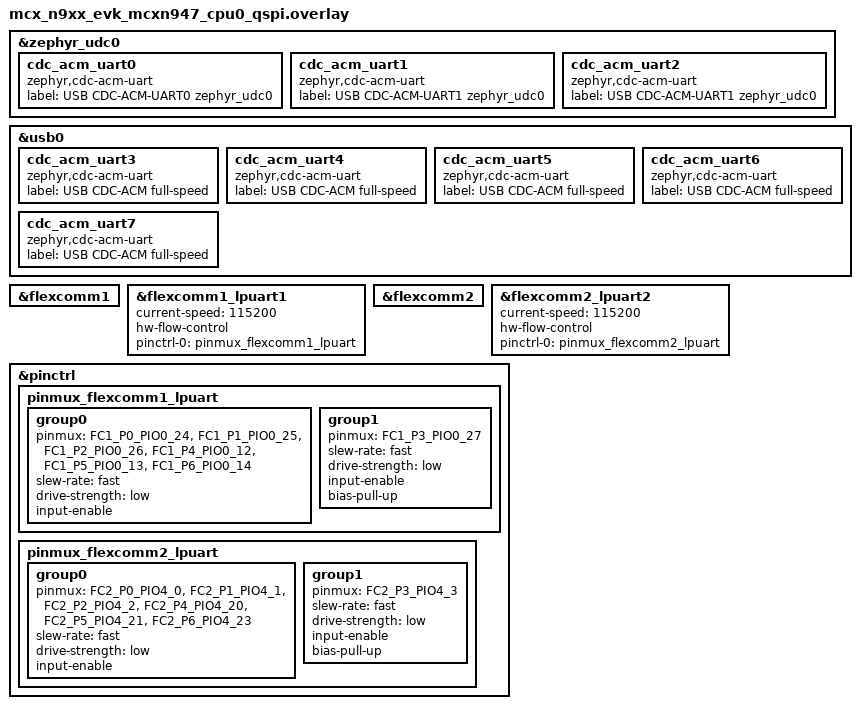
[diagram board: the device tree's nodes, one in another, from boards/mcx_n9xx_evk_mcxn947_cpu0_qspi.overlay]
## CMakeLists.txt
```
# SPDX-License-Identifier: Apache-2.0

cmake_minimum_required(VERSION 3.20.0)
find_package(Zephyr REQUIRED HINTS $ENV{ZEPHYR_BASE})
project(cdc_multi)

include(${ZEPHYR_BASE}/samples/subsys/usb/common/common.cmake)
target_include_directories(app PRIVATE src)
list(APPEND app_sources src/main.c)
list(APPEND app_sources src/dual_usbd_init.c)

if (DEFINED CONFIG_APP_UART_TEST)
	list(APPEND app_sources src/uart_test.c)
endif()

target_sources(app PRIVATE ${app_sources})
```

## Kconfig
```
# Copyright (c) 2023 Nordic Semiconductor ASA
# Copyright 2025 NXP
# SPDX-License-Identifier: Apache-2.0

config APP_UART_TEST
	bool
	prompt "Includes UART test in app"

module = UART_TEST
module-str = uart_test
source "subsys/logging/Kconfig.template.log_config"

# Source common USB sample options used to initialize new experimental USB
# device stack. The scope of these options is limited to USB samples in project
# tree, you cannot use them in your own application.
source "samples/subsys/usb/common/Kconfig.sample_usbd"

source "Kconfig.zephyr"
```

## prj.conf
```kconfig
CONFIG_USB_DEVICE_STACK_NEXT=y

CONFIG_STDOUT_CONSOLE=y
CONFIG_SERIAL=y
CONFIG_UART_LINE_CTRL=y
CONFIG_UART_INTERRUPT_DRIVEN=y

CONFIG_LOG=y
CONFIG_USBD_LOG_LEVEL_WRN=y
CONFIG_UDC_DRIVER_LOG_LEVEL_WRN=y
CONFIG_USBD_CDC_ACM_LOG_LEVEL_ERR=y

CONFIG_USB_DEVICE_INITIALIZE_AT_BOOT=n
CONFIG_CDC_ACM_SERIAL_INITIALIZE_AT_BOOT=n
CONFIG_USBD_CDC_ACM_CLASS=y


CONFIG_SAMPLE_USBD_PID=0x0001
CONFIG_SAMPLE_USBD_PRODUCT="USBD CDC Multi sample"

CONFIG_APP_UART_TEST=y
CONFIG_UART_TEST_LOG_LEVEL_DBG=y
```

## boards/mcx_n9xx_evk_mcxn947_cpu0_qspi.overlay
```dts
/*
 * Copyright 2025 NXP
 *
 * SPDX-License-Identifier: Apache-2.0
 */

/* For USBHS && USBFS */
&zephyr_udc0 {
	cdc_acm_uart0 {
		compatible = "zephyr,cdc-acm-uart";
		label = "USB CDC-ACM-UART0 zephyr_udc0";
	};

	cdc_acm_uart1 {
		compatible = "zephyr,cdc-acm-uart";
		label = "USB CDC-ACM-UART1 zephyr_udc0";
	};

	cdc_acm_uart2 {
		compatible = "zephyr,cdc-acm-uart";
		label = "USB CDC-ACM-UART1 zephyr_udc0";
	};
};

zephyr_udc1: &usb0 {
	status = "okay";
	cdc_acm_uart3 {
		compatible = "zephyr,cdc-acm-uart";
		label = "USB CDC-ACM full-speed";
	};

	cdc_acm_uart4 {
		compatible = "zephyr,cdc-acm-uart";
		label = "USB CDC-ACM full-speed";
	};

	cdc_acm_uart5 {
		compatible = "zephyr,cdc-acm-uart";
		label = "USB CDC-ACM full-speed";
	};

	cdc_acm_uart6 {
		compatible = "zephyr,cdc-acm-uart";
		label = "USB CDC-ACM full-speed";
	};

	cdc_acm_uart7 {
		compatible = "zephyr,cdc-acm-uart";
		label = "USB CDC-ACM full-speed";
	};
};

/* For UARTs test with hardware flow control */
&flexcomm1 {
	status = "okay";
};

test_uart1: &flexcomm1_lpuart1 {
	status = "okay";
	current-speed = <115200>;
	hw-flow-control;
	pinctrl-0 = < &pinmux_flexcomm1_lpuart >;
	pinctrl-names = "default";
};

&flexcomm2 {
	status = "okay";
};

test_uart2: &flexcomm2_lpuart2 {
		status = "okay";
		current-speed = <115200>;
		hw-flow-control;
		pinctrl-0 = < &pinmux_flexcomm2_lpuart >;
		pinctrl-names = "default";
};

&pinctrl {
	pinmux_flexcomm1_lpuart: pinmux_flexcomm1_lpuart {
		group0 {
			pinmux = <FC1_P0_PIO0_24>,
				<FC1_P1_PIO0_25>,
				<FC1_P2_PIO0_26>,
				<FC1_P4_PIO0_12>,
				<FC1_P5_PIO0_13>,
				<FC1_P6_PIO0_14>;
			slew-rate = "fast";
			drive-strength = "low";
			input-enable;
		};
		group1 {
			/* Pull-up CTS_b signals */
			pinmux = <FC1_P3_PIO0_27>;
			slew-rate = "fast";
			drive-strength = "low";
			input-enable;
			bias-pull-up;
		};
	};

	pinmux_flexcomm2_lpuart: pinmux_flexcomm2_lpuart {
		group0 {
			pinmux = <FC2_P0_PIO4_0>,
				<FC2_P1_PIO4_1>,
				<FC2_P2_PIO4_2>,
				<FC2_P4_PIO4_20>,
				<FC2_P5_PIO4_21>,
				<FC2_P6_PIO4_23>;
			slew-rate = "fast";
			drive-strength = "low";
			input-enable;
		};
		group1 {
			/* Pull-up CTS_b signals */
			pinmux = <FC2_P3_PIO4_3>;
			slew-rate = "fast";
			drive-strength = "low";
			input-enable;
			bias-pull-up;
		};
	};
};
```

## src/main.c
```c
/*
 * Copyright (c) 2019 Intel Corporation
 *
 * SPDX-License-Identifier: Apache-2.0
 */

/**
 * @file
 * @brief Sample echo app for CDC ACM class
 *
 * Sample app for USB CDC ACM class driver. The received data is echoed back
 * to the serial port.
 */

#include <dual_usbd.h>

#include <stdio.h>
#include <string.h>
#include <zephyr/device.h>
#include <zephyr/drivers/uart.h>
#include <zephyr/kernel.h>
#include <zephyr/sys/ring_buffer.h>

#include <zephyr/usb/usb_device.h>
#include <zephyr/usb/usbd.h>
#include <zephyr/logging/log.h>
LOG_MODULE_REGISTER(cdc_acm_echo, LOG_LEVEL_INF);

const struct device *const uart0_dev = DEVICE_DT_GET_ONE(zephyr_cdc_acm_uart);

#define RING_BUF_SIZE 1024
uint8_t ring_buffer[RING_BUF_SIZE];

struct ring_buf ringbuf;

static bool rx_throttled;

static struct usbd_context *usb0_ctx;
static struct usbd_context *usb1_ctx;

K_SEM_DEFINE(usb0_dtr_sem, 0, 1);
K_SEM_DEFINE(usb1_dtr_sem, 0, 1);

static inline void print_baudrate(const struct device *dev)
{
	uint32_t baudrate;
	int ret;

	ret = uart_line_ctrl_get(dev, UART_LINE_CTRL_BAUD_RATE, &baudrate);
	if (ret) {
		LOG_WRN("Failed to get baudrate, ret code %d", ret);
	} else {
		LOG_INF("Baudrate %u", baudrate);
	}
}


static void usb0_msg_cb(struct usbd_context *const ctx, const struct usbd_msg *msg)
{
	LOG_INF("USBD message: %s", usbd_msg_type_string(msg->type));

	if (usbd_can_detect_vbus(ctx)) {
		if (msg->type == USBD_MSG_VBUS_READY) {
			if (usbd_enable(ctx)) {
				LOG_ERR("Failed to enable device support");
			}
		}

		if (msg->type == USBD_MSG_VBUS_REMOVED) {
			if (usbd_disable(ctx)) {
				LOG_ERR("Failed to disable device support");
			}
		}
	}

	if (msg->type == USBD_MSG_CDC_ACM_CONTROL_LINE_STATE) {
		uint32_t usb0_dtr = 0U;

		uart_line_ctrl_get(msg->dev, UART_LINE_CTRL_DTR, &usb0_dtr);
		if (usb0_dtr) {
			k_sem_give(&usb0_dtr_sem);
		}
	}

	if (msg->type == USBD_MSG_CDC_ACM_LINE_CODING) {
		print_baudrate(msg->dev);
	}
}

static void usb1_msg_cb(struct usbd_context *const ctx, const struct usbd_msg *msg)
{
	LOG_INF("USBD message: %s", usbd_msg_type_string(msg->type));

	if (usbd_can_detect_vbus(ctx)) {
		if (msg->type == USBD_MSG_VBUS_READY) {
			if (usbd_enable(ctx)) {
				LOG_ERR("Failed to enable device support");
			}
		}

		if (msg->type == USBD_MSG_VBUS_REMOVED) {
			if (usbd_disable(ctx)) {
				LOG_ERR("Failed to disable device support");
			}
		}
	}

	if (msg->type == USBD_MSG_CDC_ACM_CONTROL_LINE_STATE) {
		uint32_t usb1_dtr = 0U;

		uart_line_ctrl_get(msg->dev, UART_LINE_CTRL_DTR, &usb1_dtr);
		if (usb1_dtr) {
			k_sem_give(&usb1_dtr_sem);
		}
	}

	if (msg->type == USBD_MSG_CDC_ACM_LINE_CODING) {
		print_baudrate(msg->dev);
	}
}

static int enable_usb_device_next(void)
{
	int err;

	usb0_ctx = usb0_init_device(usb0_msg_cb);
	if (usb0_ctx == NULL) {
		LOG_ERR("Failed to initialize usb0 device");
		return -ENODEV;
	}

	if (!usbd_can_detect_vbus(usb0_ctx)) {
		err = usbd_enable(usb0_ctx);
		if (err) {
			LOG_ERR("Failed to enable device support");
		} else {
			LOG_INF("usb0 enabled");
		}
	}

	usb1_ctx = usb1_init_device(usb1_msg_cb);
	if (usb1_ctx == NULL) {
		LOG_ERR("Failed to initialize usb0 device");
		return -ENODEV;
	}

	if (!usbd_can_detect_vbus(usb1_ctx)) {
		err = usbd_enable(usb1_ctx);
		if (err) {
			LOG_ERR("Failed to enable usb1 device support");
		} else {
			LOG_INF("usb1 enabled");
		}
	}

	return 0;
}

static void interrupt_handler(const struct device *dev, void *user_data)
{
	ARG_UNUSED(user_data);

	while (uart_irq_update(dev) && uart_irq_is_pending(dev)) {
		if (!rx_throttled && uart_irq_rx_ready(dev)) {
			int recv_len, rb_len;
			uint8_t buffer[64];
			size_t len = MIN(ring_buf_space_get(&ringbuf),
					 sizeof(buffer));

			if (len == 0) {
				/* Throttle because ring buffer is full */
				uart_irq_rx_disable(dev);
				rx_throttled = true;
				continue;
			}

			recv_len = uart_fifo_read(dev, buffer, len);
			if (recv_len < 0) {
				LOG_ERR("Failed to read UART FIFO");
				recv_len = 0;
			};

			rb_len = ring_buf_put(&ringbuf, buffer, recv_len);
			if (rb_len < recv_len) {
				LOG_ERR("Drop %u bytes", recv_len - rb_len);
			}

			LOG_DBG("tty fifo -> ringbuf %d bytes", rb_len);
			if (rb_len) {
				uart_irq_tx_enable(dev);
			}
		}

		if (uart_irq_tx_ready(dev)) {
			uint8_t buffer[64];
			int rb_len, send_len;

			rb_len = ring_buf_get(&ringbuf, buffer, sizeof(buffer));
			if (!rb_len) {
				LOG_DBG("Ring buffer empty, disable TX IRQ");
				uart_irq_tx_disable(dev);
				continue;
			}

			if (rx_throttled) {
				uart_irq_rx_enable(dev);
				rx_throttled = false;
			}

			send_len = uart_fifo_fill(dev, buffer, rb_len);
			if (send_len < rb_len) {
				LOG_ERR("Drop %d bytes", rb_len - send_len);
			}

			LOG_DBG("ringbuf -> tty fifo %d bytes", send_len);
		}
	}
}

int main(void)
{
	int ret;

	if (!device_is_ready(uart0_dev)) {
		LOG_ERR("CDC ACM device not ready");
		return 0;
	}

	ret = enable_usb_device_next();
	if (ret != 0) {
		LOG_ERR("Failed to enable USB");
		return 0;
	}

	ring_buf_init(&ringbuf, sizeof(ring_buffer), ring_buffer);
	LOG_INF("Wait for DTR");

#if defined(CONFIG_USB_DEVICE_STACK_NEXT)
	k_sem_take(&usb0_dtr_sem, K_FOREVER);
#else
	while (true) {
		uint32_t dtr = 0U;

		uart_line_ctrl_get(uart_dev, UART_LINE_CTRL_DTR, &dtr);
		if (dtr) {
			break;
		} else {
			/* Give CPU resources to low priority threads. */
			k_sleep(K_MSEC(100));
		}
	}
#endif

	LOG_INF("DTR set");

	/* They are optional, we use them to test the interrupt endpoint */
	ret = uart_line_ctrl_set(uart0_dev, UART_LINE_CTRL_DCD, 1);
	if (ret) {
		LOG_WRN("Failed to set DCD, ret code %d", ret);
	}

	ret = uart_line_ctrl_set(uart0_dev, UART_LINE_CTRL_DSR, 1);
	if (ret) {
		LOG_WRN("Failed to set DSR, ret code %d", ret);
	}

	/* Wait 100ms for the host to do all settings */
	k_msleep(100);

#ifndef CONFIG_USB_DEVICE_STACK_NEXT
	print_baudrate(uart0_dev);
#endif
	uart_irq_callback_set(uart0_dev, interrupt_handler);

	/* Enable rx interrupts */
	uart_irq_rx_enable(uart0_dev);

	return 0;
}
```

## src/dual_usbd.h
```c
/*
 * Copyright (c) 2023 Nordic Semiconductor ASA.
 *
 * SPDX-License-Identifier: Apache-2.0
 */

#ifndef ZEPHYR_SAMPLES_SUBSYS_USB_COMMON_SAMPLE_USBD_H
#define ZEPHYR_SAMPLES_SUBSYS_USB_COMMON_SAMPLE_USBD_H

#include <stdint.h>
#include <zephyr/usb/usbd.h>

/*
 * The scope of this header is limited to use in USB samples together with the
 * new experimental USB device stack, you should not use it in your own
 * application. However, you can use the code as a template.
 */

/*
 * This function uses Kconfig.sample_usbd options to configure and initialize a
 * USB device. It configures sample's device context, default string descriptors,
 * USB device configuration, registers any available class instances, and
 * finally initializes USB device. It is limited to a single device with a
 * single configuration instantiated in sample_usbd_init.c, which should be
 * enough for a simple USB device sample.
 *
 * It returns the configured and initialized USB device context on success,
 * otherwise it returns NULL.
 */
/* struct usbd_context *sample_usbd_init_device(usbd_msg_cb_t msg_cb, enum usbd_speed speed); */

/*
 * This function is similar to sample_usbd_init_device(), but does not
 * initialize the device. It allows the application to set additional features,
 * such as additional descriptors.
 */
/* struct usbd_context *sample_usbd_setup_device(usbd_msg_cb_t msg_cb); */

struct usbd_context *usb0_init_device(usbd_msg_cb_t msg_cb);
struct usbd_context *usb1_init_device(usbd_msg_cb_t msg_cb);

#endif /* ZEPHYR_SAMPLES_SUBSYS_USB_COMMON_SAMPLE_USBD_H */
```

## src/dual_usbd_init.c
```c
/*
 * Copyright (c) 2023 Nordic Semiconductor ASA
 *
 * SPDX-License-Identifier: Apache-2.0
 */

#include <stdint.h>

#include <zephyr/init.h>
#include <zephyr/kernel.h>
#include <zephyr/device.h>
#include <zephyr/usb/usbd.h>

#include <zephyr/logging/log.h>
LOG_MODULE_REGISTER(dual_usbd, LOG_LEVEL_DBG);

#define ZEPHYR_PROJECT_USB_VID 0x2fe3

USBD_DEVICE_DEFINE(usb0_usbd, DEVICE_DT_GET(DT_NODELABEL(zephyr_udc0)),
	ZEPHYR_PROJECT_USB_VID, CONFIG_SAMPLE_USBD_PID);

USBD_DEVICE_DEFINE(usb1_usbd, DEVICE_DT_GET(DT_NODELABEL(zephyr_udc1)),
	ZEPHYR_PROJECT_USB_VID, CONFIG_SAMPLE_USBD_PID);

USBD_DESC_LANG_DEFINE(usb0_lang);
USBD_DESC_MANUFACTURER_DEFINE(usb0_mfr, CONFIG_SAMPLE_USBD_MANUFACTURER);
USBD_DESC_PRODUCT_DEFINE(usb0_product, CONFIG_SAMPLE_USBD_PRODUCT);
USBD_DESC_SERIAL_NUMBER_DEFINE(usb0_sn);

USBD_DESC_LANG_DEFINE(usb1_lang);
USBD_DESC_MANUFACTURER_DEFINE(usb1_mfr, CONFIG_SAMPLE_USBD_MANUFACTURER);
USBD_DESC_PRODUCT_DEFINE(usb1_product, CONFIG_SAMPLE_USBD_PRODUCT);
USBD_DESC_SERIAL_NUMBER_DEFINE(usb1_sn);


USBD_DESC_CONFIG_DEFINE(usb_fs_cfg_desc, "FS Configuration");
USBD_DESC_CONFIG_DEFINE(usb_hs_cfg_desc, "HS Configuration");

/* doc configuration instantiation start */
static const uint8_t attributes =
	(IS_ENABLED(CONFIG_SAMPLE_USBD_SELF_POWERED) ? USB_SCD_SELF_POWERED : 0) |
	(IS_ENABLED(CONFIG_SAMPLE_USBD_REMOTE_WAKEUP) ? USB_SCD_REMOTE_WAKEUP : 0);

/* Speed configuration */
USBD_CONFIGURATION_DEFINE(usb_fs_config, attributes,
			CONFIG_SAMPLE_USBD_MAX_POWER, &usb_fs_cfg_desc);
USBD_CONFIGURATION_DEFINE(usb_hs_config, attributes,
			CONFIG_SAMPLE_USBD_MAX_POWER, &usb_hs_cfg_desc);
/* doc configuration instantiation end */

static int usb0_register_cdc_acm_n(struct usbd_context *const uds_ctx,
			const enum usbd_speed speed)
{
	struct usbd_config_node *cfg_nd;
	int err;

	if (speed == USBD_SPEED_HS) {
		cfg_nd = &usb_hs_config;
	} else {
		cfg_nd = &usb_fs_config;
	}

	err = usbd_add_configuration(uds_ctx, speed, cfg_nd);
	if (err) {
		LOG_ERR("Failed to add configuration");
		return err;
	}

	err = usbd_register_class(uds_ctx, "cdc_acm_0", speed, 1);
	if (err) {
		LOG_ERR("Failed to register cdc_acm0");
		return err;
	}

	err = usbd_register_class(uds_ctx, "cdc_acm_1", speed, 1);
	if (err) {
		LOG_ERR("Failed to register cdc_acm1");
		return err;
	}

	err = usbd_register_class(uds_ctx, "cdc_acm_2", speed, 1);
	if (err) {
		LOG_ERR("Failed to register cdc_acm2");
		return err;
	}

	return usbd_device_set_code_triple(uds_ctx, speed, USB_BCC_MISCELLANEOUS, 0x02, 0x01);
}

static int usb1_register_cdc_acm_n(struct usbd_context *const uds_ctx,
	const enum usbd_speed speed)
{
	struct usbd_config_node *cfg_nd;
	int err;

	if (speed == USBD_SPEED_HS) {
		cfg_nd = &usb_hs_config;
	} else {
		cfg_nd = &usb_fs_config;
	}

	err = usbd_add_configuration(uds_ctx, speed, cfg_nd);
	if (err) {
		LOG_ERR("Failed to add configuration");
		return err;
	}

	err = usbd_register_class(uds_ctx, "cdc_acm_3", speed, 1);
	if (err) {
		LOG_ERR("Failed to register cdc_acm3");
		return err;
	}

	err = usbd_register_class(uds_ctx, "cdc_acm_4", speed, 1);
	if (err) {
		LOG_ERR("Failed to register cdc_acm4");
		return err;
	}

	err = usbd_register_class(uds_ctx, "cdc_acm_5", speed, 1);
	if (err) {
		LOG_ERR("Failed to register cdc_acm5");
		return err;
	}

	err = usbd_register_class(uds_ctx, "cdc_acm_6", speed, 1);
	if (err) {
		LOG_ERR("Failed to register cdc_acm6");
		return err;
	}

	err = usbd_register_class(uds_ctx, "cdc_acm_7", speed, 1);
	if (err) {
		LOG_ERR("Failed to register cdc_acm7");
		return err;
	}

	return usbd_device_set_code_triple(uds_ctx, speed, USB_BCC_MISCELLANEOUS, 0x02, 0x01);
}

struct usbd_context *usb0_init_device(usbd_msg_cb_t msg_cb)
{
	int err = 0;
	enum usbd_speed speed;

	err = usbd_add_descriptor(&usb0_usbd, &usb0_lang);
	if (err) {
		LOG_ERR("Failed to initialize language descriptor (%d)", err);
		return NULL;
	}

	err = usbd_add_descriptor(&usb0_usbd, &usb0_mfr);
	if (err) {
		LOG_ERR("Failed to initialize manufacturer descriptor (%d)", err);
		return NULL;
	}

	err = usbd_add_descriptor(&usb0_usbd, &usb0_product);
	if (err) {
		LOG_ERR("Failed to initialize product descriptor (%d)", err);
		return NULL;
	}

	err = usbd_add_descriptor(&usb0_usbd, &usb0_sn);
	if (err) {
		LOG_ERR("Failed to initialize SN descriptor (%d)", err);
		return NULL;
	}


	speed = usbd_caps_speed(&usb0_usbd);
	err = usb0_register_cdc_acm_n(&usb0_usbd, speed);
	if (err) {
		return NULL;
	}

	err = usbd_msg_register_cb(&usb0_usbd, msg_cb);
	if (err) {
		LOG_ERR("Failed to register message callback");
		return NULL;
	}

	err = usbd_init(&usb0_usbd);
	if (err) {
		LOG_ERR("Failed to initialize device support");
		return NULL;
	}

	return &usb0_usbd;
}

struct usbd_context *usb1_init_device(usbd_msg_cb_t msg_cb)
{
	int err = 0;
	enum usbd_speed speed;

	err = usbd_add_descriptor(&usb1_usbd, &usb1_lang);
	if (err) {
		LOG_ERR("Failed to initialize language descriptor (%d)", err);
		return NULL;
	}

	err = usbd_add_descriptor(&usb1_usbd, &usb1_mfr);
	if (err) {
		LOG_ERR("Failed to initialize manufacturer descriptor (%d)", err);
		return NULL;
	}

	err = usbd_add_descriptor(&usb1_usbd, &usb1_product);
	if (err) {
		LOG_ERR("Failed to initialize product descriptor (%d)", err);
		return NULL;
	}

	err = usbd_add_descriptor(&usb1_usbd, &usb1_sn);
	if (err) {
		LOG_ERR("Failed to initialize SN descriptor (%d)", err);
		return NULL;
	}


	speed = usbd_caps_speed(&usb1_usbd);
	err = usb1_register_cdc_acm_n(&usb1_usbd, speed);
	if (err) {
		return NULL;
	}

	err = usbd_msg_register_cb(&usb1_usbd, msg_cb);
	if (err) {
		LOG_ERR("Failed to register usb1 message callback");
		return NULL;
	}

	err = usbd_init(&usb1_usbd);
	if (err) {
		LOG_ERR("Failed to initialize device support");
		return NULL;
	}

	return &usb1_usbd;
}

/*
 * SYS_INIT(usb0_init_device, APPLICATION, CONFIG_APPLICATION_INIT_PRIORITY);
 * SYS_INIT(usb1_init_device, APPLICATION, CONFIG_APPLICATION_INIT_PRIORITY);
 */
```

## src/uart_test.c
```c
/*
 * Copyright 2025 NXP
 * Copyright (c) 2024 Nordic Semiconductor ASA
 *
 * SPDX-License-Identifier: Apache-2.0
 */

#include <zephyr/kernel.h>
#include <zephyr/device.h>
#include <zephyr/drivers/uart.h>

#ifdef CONFIG_LOG
	#include <zephyr/logging/log.h>
	LOG_MODULE_REGISTER(uart_test, CONFIG_UART_TEST_LOG_LEVEL);
#endif

#define UART1_NODE DT_NODELABEL(test_uart1)
#define UART2_NODE DT_NODELABEL(test_uart2)
static const struct device *const uart1_dev = DEVICE_DT_GET(UART1_NODE);
static const struct device *const uart2_dev = DEVICE_DT_GET(UART2_NODE);

#define SLEEP_TIME_MS 1000
#define TEST_BUFFER_LEN 20
const uint8_t test_pattern[TEST_BUFFER_LEN] = "UART Hello";
static uint8_t test1_buffer[TEST_BUFFER_LEN];
static uint8_t test2_buffer[TEST_BUFFER_LEN];
static volatile uint8_t uart1_error_counter;
static volatile uint8_t uart2_error_counter;
static int tx1_byte_offset;
static int rx1_byte_offset;
static int tx2_byte_offset;
static int rx2_byte_offset;

/* Define UART Test Thread */
#define UART_STACKSIZE	8096U
#define UART_PRIORITY	2U

void UART_Test_thread(void *dev, void *dummy2, void *dummy3);
K_THREAD_DEFINE(UART_Test_id, UART_STACKSIZE, UART_Test_thread,
		NULL, NULL, NULL, UART_PRIORITY, 0U, 0U);

/*
 * ISR for UART TX action
 */
static void uart_tx_interrupt_service(const struct device *dev, int *tx_byte_offset)
{
	uint8_t bytes_sent = 0;
	uint8_t *tx_data_pointer = (uint8_t *)(test_pattern + *tx_byte_offset);

	if (*tx_byte_offset < TEST_BUFFER_LEN) {
		bytes_sent = uart_fifo_fill(dev, tx_data_pointer, 1);
		*tx_byte_offset += bytes_sent;
	} else {
		*tx_byte_offset = 0;
		uart_irq_tx_disable(dev);
	}
}

/*
 * ISR for UART RX action
 */
static void uart_rx_interrupt_service(const struct device *dev, uint8_t *receive_buffer_pointer,
				      int *rx_byte_offset)
{
	int rx_data_length = 0;

	do {
		rx_data_length = uart_fifo_read(dev, receive_buffer_pointer + *rx_byte_offset,
						TEST_BUFFER_LEN);
		*rx_byte_offset += rx_data_length;
	} while (rx_data_length);
}

/*
 * Callback function for UART1 interrupt based transmission test
 */
static void interrupt_driven_uart1_callback(const struct device *dev, void *user_data)
{
	int err;

	uart_irq_update(dev);
	err = uart_err_check(dev);
	if (err != 0) {
		uart1_error_counter++;
	}
	while (uart_irq_is_pending(dev)) {
		if (uart_irq_rx_ready(dev)) {
			uart_rx_interrupt_service(dev, (uint8_t *)user_data, &rx1_byte_offset);
		}
		if (uart_irq_tx_ready(dev)) {
			uart_tx_interrupt_service(dev, &tx1_byte_offset);
		}
	}
}

/*
 * Callback function for UART2 interrupt based transmission test
 */
static void interrupt_driven_uart2_callback(const struct device *dev, void *user_data)
{
	int err;

	uart_irq_update(dev);
	err = uart_err_check(dev);
	if (err != 0) {
		uart2_error_counter++;
	}
	while (uart_irq_is_pending(dev)) {
		if (uart_irq_rx_ready(dev)) {
			uart_rx_interrupt_service(dev, (uint8_t *)user_data, &rx2_byte_offset);
		}
		if (uart_irq_tx_ready(dev)) {
			uart_tx_interrupt_service(dev, &tx2_byte_offset);
		}
	}
}

void UART_Test_thread(void *dummy1, void *dummy2, void *dummy3)
{
	ARG_UNUSED(dummy1);
	ARG_UNUSED(dummy2);
	ARG_UNUSED(dummy3);

	int err, ret;
	bool pin_assert_state = false;
	uint32_t pin_state;

	struct uart_config test_uart_config = {.baudrate = DT_PROP(UART1_NODE, current_speed),
						.parity = UART_CFG_PARITY_NONE,
						.stop_bits = UART_CFG_STOP_BITS_1,
						.data_bits = UART_CFG_DATA_BITS_8,
						.flow_ctrl = UART_CFG_FLOW_CTRL_RTS_CTS };

	err = uart_configure(uart1_dev, &test_uart_config);
	if (err) {
		LOG_ERR("'uart1_configure' api call - unexpected error: %d", err);
	}

	err = uart_configure(uart2_dev, &test_uart_config);
	if (err) {
		LOG_ERR("'uart2_configure' api call - unexpected error: %d", err);
	}

	err = uart_irq_callback_set(uart1_dev, interrupt_driven_uart1_callback);
	if (err) {
		LOG_ERR("Unexpected error when setting callback for UART1 %d", err);
	}

	err = uart_irq_callback_set(uart2_dev, interrupt_driven_uart2_callback);
	if (err) {
		LOG_ERR("Unexpected error when setting callback for UART2 %d", err);
	}

	while(1) {
		err = uart_irq_callback_user_data_set(uart1_dev,
						interrupt_driven_uart1_callback,
						(void *)test1_buffer);
		if (err) {
			LOG_ERR("Unexpected error when setting user data for UART1 callback %d", err);
		}

		err = uart_irq_callback_user_data_set(uart2_dev,
						interrupt_driven_uart2_callback,
						(void *)test2_buffer);
		if (err) {
			LOG_ERR("Unexpected error when setting user data for UART2 callback %d", err);
		}

		memset(test1_buffer, 0U, TEST_BUFFER_LEN);
		memset(test2_buffer, 0U, TEST_BUFFER_LEN);

#ifdef CONFIG_UART_LINE_CTRL
		/* Toggle pins driven in test */
		pin_assert_state = !pin_assert_state;
		ret = uart_line_ctrl_set(uart1_dev, UART_LINE_CTRL_DTR, pin_assert_state);
		if (ret) {
			LOG_ERR("uart_line_ctrl_set(uart1, DTR) returned error %d", err);
		}
		ret = uart_line_ctrl_set(uart2_dev, UART_LINE_CTRL_DTR, !pin_assert_state);
		if (ret) {
			LOG_ERR("uart_line_ctrl_set(uart, DTR) returned error %d", err);
		}
#endif /* CONFIG_UART_LINE_CTRL */

		uart_irq_err_enable(uart1_dev);
		uart_irq_err_enable(uart2_dev);

		uart_irq_rx_enable(uart1_dev);
		uart_irq_rx_enable(uart2_dev);

		uart_irq_tx_enable(uart1_dev);
		uart_irq_tx_enable(uart2_dev);

		/* wait for the tramission to finish (no polling is intentional) */
		k_sleep(K_MSEC(SLEEP_TIME_MS));

		err = 0;
#ifdef CONFIG_UART_LINE_CTRL
		/* confirm pin inputs */
		ret = uart_line_ctrl_get(uart1_dev, UART_LINE_CTRL_DSR, &pin_state);
		if (ret) {
			LOG_ERR("uart_line_ctrl_get(uart1, DSR) returned error %d", err);
			err++;
		}
		if (pin_assert_state != (bool) pin_state) {
			LOG_ERR("DSR does not match DTR for uart1");
			err++;
		}

		ret = uart_line_ctrl_get(uart2_dev, UART_LINE_CTRL_DSR, &pin_state);
		if (ret) {
			LOG_ERR("uart_line_ctrl_get(uart2, DSR) returned error %d", err);
			err++;
		}
		if (pin_assert_state == (bool) pin_state) {
			LOG_ERR("DSR does not match DTR for uart2");
			err++;
		}

		ret = uart_line_ctrl_get(uart1_dev, UART_LINE_CTRL_DCD, &pin_state);
		if (ret) {
			LOG_ERR("uart_line_ctrl_get(uart1, DCD) returned error %d", err);
			err++;
		}
		if (pin_assert_state != (bool) pin_state) {
			LOG_ERR("DCD does not match DTR for uart1");
			err++;
		}

		ret = uart_line_ctrl_get(uart2_dev, UART_LINE_CTRL_DCD, &pin_state);
		if (ret) {
			LOG_ERR("uart_line_ctrl_get(uart2, DCD) returned error %d", err);
			err++;
		}
		if (pin_assert_state == (bool) pin_state) {
			LOG_ERR("DCD does not match DTR for uart2");
			err++;
		}
#endif /* CONFIG_UART_LINE_CTRL */

		/* Confirm received buffers */
		for (int index = 0; index < TEST_BUFFER_LEN; index++) {
			if (test1_buffer[index] != test_pattern[index]) {
				LOG_ERR("test1_buffer index %d does not match pattern", index);
				err++;
				break;
			}
			if (test2_buffer[index] != test_pattern[index]) {
				LOG_ERR("test2_buffer index %d does not match pattern", index);
				err++;
				break;
			}
		}

		if (err == 0) {
			LOG_INF("UART test passed");
		}
		tx1_byte_offset = 0;
		rx1_byte_offset = 0;
		tx2_byte_offset = 0;
		rx2_byte_offset = 0;
			}
}
```
